# ATmega64A device description
Architecture: AVR8; Family: megaAVR
Registers are 8-bit, access not given, no defined reset value unless marked. A register's access mark holds for its fields unless they carry their own. Offsets are from the block's base; [hi:lo] are bit positions; {n}, {i} and the like mark numbered series; 'fields as' and 'values as' point back to an identical list.

## BOOT_LOAD — Bootloader
Instances: BOOT_LOAD 0x00
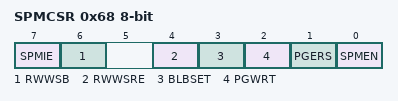
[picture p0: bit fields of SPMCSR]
0x68 SPMCSR — Store Program Memory Control Register
  [7] SPMIE — SPM Interrupt Enable
  [6] RWWSB — Read While Write Section Busy
  [4] RWWSRE — Read While Write section read enable
  [3] BLBSET — Boot Lock Bit Set
  [2] PGWRT — Page Write
  [1] PGERS — Page Erase
  [0] SPMEN — Store Program Memory Enable

## JTAG — JTAG Interface
Instances: JTAG 0x00
0x42 OCDR — On-Chip Debug Related Register in I/O Memory
  [7:0] OCDR — On-Chip Debug Register Bits
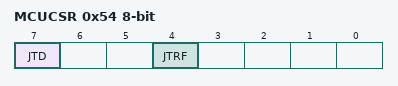
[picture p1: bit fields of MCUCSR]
0x54 MCUCSR — MCU Control And Status Register
  [7] JTD — JTAG Interface Disable
  [4] JTRF — JTAG Reset Flag

## MISC — Other Registers
Instances: MISC 0x00
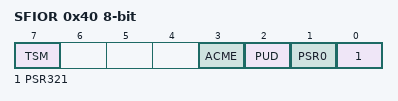
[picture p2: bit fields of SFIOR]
0x40 SFIOR — Special Function IO Register
  [7] TSM — Timer/Counter Synchronization Mode
  [3] ACME — Analog Comparator Multiplexer Enable
  [2] PUD — Pull Up Disable
  [1] PSR0 — Prescaler Reset Timer/Counter0
  [0] PSR321 — Prescaler Reset Timer/Counter3, Timer/Counter2, and Timer/Counter1

## EXINT — External Interrupts
Instances: EXINT 0x00
0x58 EIFR — External Interrupt Flag Register
  [7:0] INTF — External Interrupt Flags
0x59 EIMSK — External Interrupt Mask Register
  [7:0] INT — External Interrupt Request 7 Enable
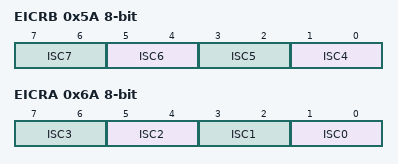
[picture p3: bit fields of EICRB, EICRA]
0x5A EICRB — External Interrupt Control Register B
  [all] fields
    0=Low Level of INTX; 1=Any Logical Change of INTX; 2=Falling Edge of INTX; 3=Rising Edge of INTX
  [2n-7:2n-8] ISC{n} (n=4..7) — External Interrupt 7-4 Sense Control Bit
0x6A EICRA — External Interrupt Control Register A
  [all] fields
    values as the fields of EICRB
  [2n+1:2n] ISC{n} (n=0..3) — External Interrupt Sense Control Bit

## EEPROM
Instances: EEPROM 0x00
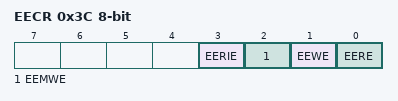
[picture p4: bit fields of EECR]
0x3C EECR — EEPROM Control Register
  [3] EERIE — EEPROM Ready Interrupt Enable
  [2] EEMWE — EEPROM Master Write Enable
  [1] EEWE — EEPROM Write Enable
  [0] EERE — EEPROM Read Enable
0x3D EEDR — EEPROM Data Register
0x3E EEAR 16-bit bits used 10:0 — EEPROM Read/Write Access Bytes

## PORTA — I/O Port
Instances: PORTA 0x00
0x39 PINA — Port A Input Pins
0x3A DDRA — Port A Data Direction Register
0x3B PORTA — Port A Data Register

## PORTB — I/O Port
Instances: PORTB 0x00
0x36 PINB — Port B Input Pins
0x37 DDRB — Port B Data Direction Register
0x38 PORTB — Port B Data Register

## PORTC — I/O Port
Instances: PORTC 0x00
0x33 PINC — Port C Input Pins
0x34 DDRC — Port C Data Direction Register
0x35 PORTC — Port C Data Register

## PORTD — I/O Port
Instances: PORTD 0x00
0x30 PIND — Port D Input Pins
0x31 DDRD — Port D Data Direction Register
0x32 PORTD — Port D Data Register

## PORTE — I/O Port
Instances: PORTE 0x00
0x21 PINE — Input Pins, Port E
0x22 DDRE — Data Direction Register, Port E
0x23 PORTE — Data Register, Port E

## PORTF — I/O Port
Instances: PORTF 0x00
0x20 PINF — Input Pins, Port F
0x61 DDRF — Data Direction Register, Port F
0x62 PORTF — Data Register, Port F

## PORTG — I/O Port
Instances: PORTG 0x00
0x63 PING bits used 4:0 — Input Pins, Port G
0x64 DDRG bits used 4:0 — Data Direction Register, Port G
0x65 PORTG bits used 4:0 — Data Register, Port G

## TC0 (TC8_ASYNC module) — Timer/Counter, 8-bit Async
Instances: TC0 0x00
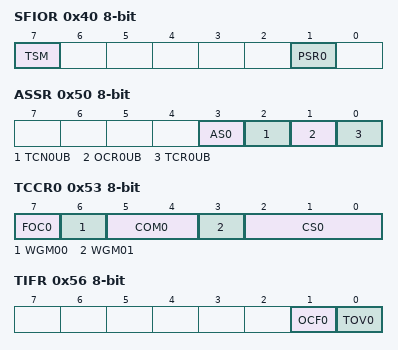
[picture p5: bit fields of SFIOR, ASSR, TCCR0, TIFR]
0x40 SFIOR — Special Function IO Register
  [7] TSM — Timer/Counter Synchronization Mode
  [1] PSR0 — Prescaler Reset Timer/Counter0
0x50 ASSR — Asynchronus Status Register
  [3] AS0 — Asynchronus Timer/Counter 0
  [2] TCN0UB — Timer/Counter0 Update Busy
  [1] OCR0UB — Output Compare register 0 Busy
  [0] TCR0UB — Timer/Counter Control Register 0 Update Busy
0x51 OCR0 — Output Compare Register
0x52 TCNT0 — Timer/Counter Register
0x53 TCCR0 — Timer/Counter Control Register
  [7] FOC0 — Force Output Compare
  [6] WGM00 — Waveform Generation Mode 0
    0=Normal; 2=PWM, Phase Correct; 1=CTC; 3=Fast PWM
  [5:4] COM0 — Compare Match Output Modes
  [3] WGM01 — Waveform Generation Mode 1
  [2:0] CS0 — Clock Selects
    0=No Clock Source (Stopped); 1=Running, No Prescaling; 2=Running, CLK/8; 3=Running, CLK/32; 4=Running, CLK/64; 5=Running, CLK/128; 6=Running, CLK/256; 7=Running, CLK/1024
0x56 TIFR — Timer/Counter Interrupt Flag register
  [1] OCF0 — Output Compare Flag 0
  [0] TOV0 — Timer/Counter0 Overflow Flag
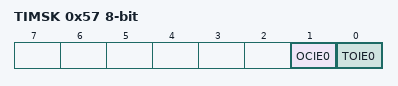
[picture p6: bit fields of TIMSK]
0x57 TIMSK — Timer/Counter Interrupt Mask Register
  [1] OCIE0 — Timer/Counter0 Output Compare Match Interrupt register
  [0] TOIE0 — Timer/Counter0 Overflow Interrupt Enable
